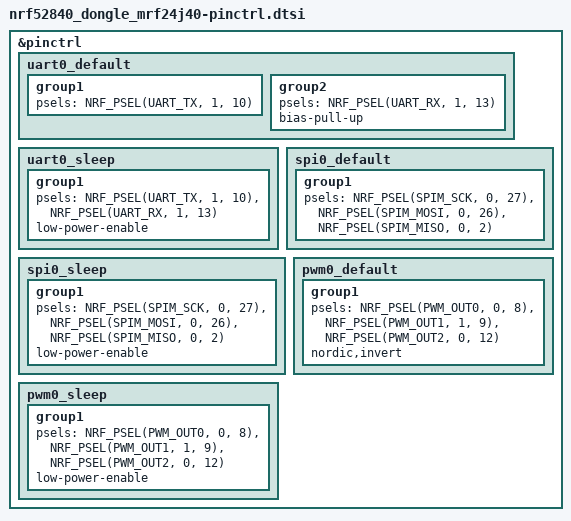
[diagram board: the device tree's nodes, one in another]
/*
 * Copyright (c) 2022 Nordic Semiconductor
 * SPDX-License-Identifier: Apache-2.0
 */

&pinctrl {
	uart0_default: uart0_default {
		group1 {
			psels = <NRF_PSEL(UART_TX, 1, 10)>;
		};
		group2 {
			psels = <NRF_PSEL(UART_RX, 1, 13)>;
			bias-pull-up;
		};
	};

	uart0_sleep: uart0_sleep {
		group1 {
			psels = <NRF_PSEL(UART_TX, 1, 10)>,
				<NRF_PSEL(UART_RX, 1, 13)>;
			low-power-enable;
		};
	};

	spi0_default: spi0_default {
		group1 {
			psels = <NRF_PSEL(SPIM_SCK, 0, 27)>,
				<NRF_PSEL(SPIM_MOSI, 0, 26)>,
				<NRF_PSEL(SPIM_MISO, 0, 2)>;
		};
	};

	spi0_sleep: spi0_sleep {
		group1 {
			psels = <NRF_PSEL(SPIM_SCK, 0, 27)>,
				<NRF_PSEL(SPIM_MOSI, 0, 26)>,
				<NRF_PSEL(SPIM_MISO, 0, 2)>;
			low-power-enable;
		};
	};

	pwm0_default: pwm0_default {
		group1 {
			psels = <NRF_PSEL(PWM_OUT0, 0, 8)>,
				<NRF_PSEL(PWM_OUT1, 1, 9)>,
				<NRF_PSEL(PWM_OUT2, 0, 12)>;
			nordic,invert;
		};
	};

	pwm0_sleep: pwm0_sleep {
		group1 {
			psels = <NRF_PSEL(PWM_OUT0, 0, 8)>,
				<NRF_PSEL(PWM_OUT1, 1, 9)>,
				<NRF_PSEL(PWM_OUT2, 0, 12)>;
			low-power-enable;
		};
	};
};
